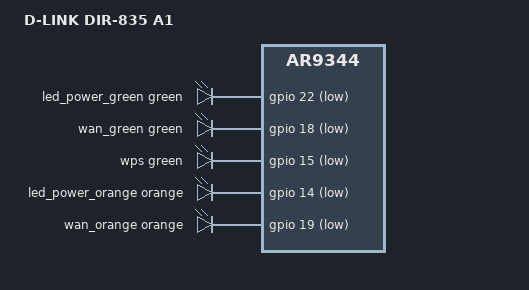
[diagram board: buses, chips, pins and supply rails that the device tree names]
// SPDX-License-Identifier: GPL-2.0-or-later OR MIT

#include <dt-bindings/leds/common.h>

#include "ar9344_dlink_dir-8x5.dtsi"

/ {
	model = "D-LINK DIR-835 A1";
	compatible = "dlink,dir-835-a1", "qca,ar9344";

	aliases {
		led-boot = &led_power_orange;
		led-failsafe = &led_power_orange;
		led-running = &led_power_green;
		led-upgrade = &led_power_orange;
	};

	leds {
		compatible = "gpio-leds";

		led_power_green: power_green {
			function = LED_FUNCTION_POWER;
			color = <LED_COLOR_ID_GREEN>;
			gpios = <&gpio 22 GPIO_ACTIVE_LOW>;
		};

		wan_green {
			function = LED_FUNCTION_WAN;
			color = <LED_COLOR_ID_GREEN>;
			gpios = <&gpio 18 GPIO_ACTIVE_LOW>;
		};

		wps {
			function = LED_FUNCTION_WPS;
			color = <LED_COLOR_ID_GREEN>;
			gpios = <&gpio 15 GPIO_ACTIVE_LOW>;
		};

		led_power_orange: power_orange {
			function = LED_FUNCTION_POWER;
			color = <LED_COLOR_ID_ORANGE>;
			gpios = <&gpio 14 GPIO_ACTIVE_LOW>;
		};

		wan_orange {
			function = LED_FUNCTION_WAN;
			color = <LED_COLOR_ID_ORANGE>;
			gpios = <&gpio 19 GPIO_ACTIVE_LOW>;
		};
	};
};
